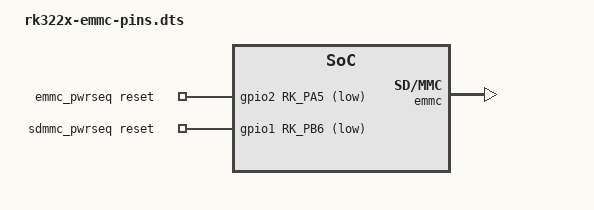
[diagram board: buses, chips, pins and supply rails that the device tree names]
/dts-v1/;
/plugin/;

#include <dt-bindings/gpio/gpio.h>
#include <dt-bindings/pinctrl/rockchip.h>

&{/} {

	emmc_pwrseq: emmc-pwrseq {
		compatible = "mmc-pwrseq-emmc";
		reset-gpios = <&gpio2 RK_PA5 GPIO_ACTIVE_LOW>;
	};

	sdmmc_pwrseq: sdmmc-pwrseq {
		compatible = "mmc-pwrseq-emmc";
		reset-gpios = <&gpio1 RK_PB6 GPIO_ACTIVE_LOW>;
	};

};

&emmc {
	status = "okay";
	pinctrl-names = "default";
	pinctrl-0 = <&emmc_clk &emmc_cmd &emmc_bus8 &emmc_pwr &emmc_rst>;
	mmc-pwrseq = <&emmc_pwrseq>;
};

&sdmmc {
	mmc-pwrseq = <&sdmmc_pwrseq>;
};

&nfc {
	status = "disabled";
};
